AUTOSAR XML (schema 4-0-3)
package /ComponentTypes
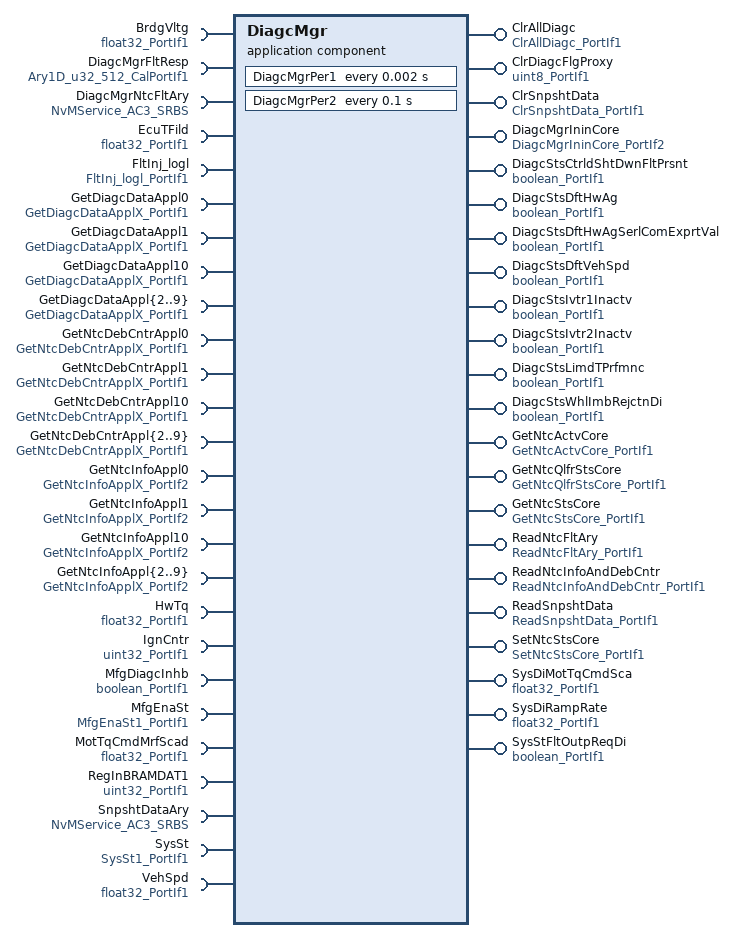
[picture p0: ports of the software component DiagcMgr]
  application sw component type DiagcMgr
    22 x provide port:
      ClrAllDiagc: server-com-spec{operation=Oper, queue-length=1}, provided-interface=ClrAllDiagc_PortIf1
      ClrDiagcFlgProxy: nonqueued-sender-com-spec{data-element=Val, init-value=0}, provided-interface=uint8_PortIf1
      ClrSnpshtData: server-com-spec{operation=Oper, queue-length=1}, provided-interface=ClrSnpshtData_PortIf1
      DiagcMgrIninCore: server-com-spec{operation=Oper, queue-length=1}, provided-interface=DiagcMgrIninCore_PortIf2
      DiagcStsCtrldShtDwnFltPrsnt: nonqueued-sender-com-spec{data-element=Logl, init-value=0}, provided-interface=boolean_PortIf1
      DiagcStsDftHwAg: nonqueued-sender-com-spec{data-element=Logl, init-value=0}, provided-interface=boolean_PortIf1
      DiagcStsDftHwAgSerlComExprtVal: nonqueued-sender-com-spec{data-element=Logl, init-value=0}, provided-interface=boolean_PortIf1
      DiagcStsDftVehSpd: nonqueued-sender-com-spec{data-element=Logl, init-value=0}, provided-interface=boolean_PortIf1
      DiagcStsIvtr1Inactv: nonqueued-sender-com-spec{data-element=Logl, init-value=0}, provided-interface=boolean_PortIf1
      DiagcStsIvtr2Inactv: nonqueued-sender-com-spec{data-element=Logl, init-value=0}, provided-interface=boolean_PortIf1
      DiagcStsLimdTPrfmnc: nonqueued-sender-com-spec{data-element=Logl, init-value=0}, provided-interface=boolean_PortIf1
      DiagcStsWhlImbRejctnDi: nonqueued-sender-com-spec{data-element=Logl, init-value=0}, provided-interface=boolean_PortIf1
      GetNtcActvCore: server-com-spec{operation=Oper, queue-length=1}, provided-interface=GetNtcActvCore_PortIf1
      GetNtcQlfrStsCore: server-com-spec{operation=Oper, queue-length=1}, provided-interface=GetNtcQlfrStsCore_PortIf1
      GetNtcStsCore: server-com-spec{operation=Oper, queue-length=1}, provided-interface=GetNtcStsCore_PortIf1
      ReadNtcFltAry: server-com-spec{operation=Oper, queue-length=1}, provided-interface=ReadNtcFltAry_PortIf1
      ReadNtcInfoAndDebCntr: server-com-spec{operation=Oper, queue-length=1}, provided-interface=ReadNtcInfoAndDebCntr_PortIf1
      ReadSnpshtData: server-com-spec{operation=Oper, queue-length=1}, provided-interface=ReadSnpshtData_PortIf1
      SetNtcStsCore: server-com-spec{operation=Oper, queue-length=1}, provided-interface=SetNtcStsCore_PortIf1
      SysDiMotTqCmdSca: nonqueued-sender-com-spec{data-element=Val, init-value=1}, provided-interface=float32_PortIf1
      SysDiRampRate: nonqueued-sender-com-spec{data-element=Val, init-value=0.1}, provided-interface=float32_PortIf1
      SysStFltOutpReqDi: nonqueued-sender-com-spec{data-element=Logl, init-value=0}, provided-interface=boolean_PortIf1
    47 x require port:
      BrdgVltg: nonqueued-receiver-com-spec{data-element=Val, filter=data-filter-type=ALWAYS, init-value=6}, required-interface=float32_PortIf1
      DiagcMgrFltResp: parameter-require-com-spec{init-value=[0, 2147487488, 2147487488, 2147487488, 2147487488, 2147487488, 2147487488, 2147487488, 2147487488, 2147487488, 2147487488, 2147487488, 2147487488, 2147487488, 2147487488, 2147487488, 2147487488, 2147487488, 2147487488, 2147487488, 2147487488, 2147487488, 2147487488, 2147487488, 2147487488, 2147487488, 2147487488, 2147487488, 2147487488, 2147487488, 2147487488, 2147487488, 2147487488, 2147487488, 2147487488, 2147487488, 2147487488, 2147487488, 2147487488, 2147487488, 2147487488, 2147487488, 2147487488, 2147487488, 2147487488, 2147487488, 2147487488, 2147487488, 2147487488, 2147487488, 2147487488, 2147487488, 2147487488, 2147487488, 2147487488, 2147487488, 2147487488, 2147487488, 2147487488, 2147487488, 2147487488, 2147487488, 2147487488, 2147487488, 2147487488, 2147487488, 2147487488, 2147487488, 2147487488, 2147487488, 2147487488, 2147487488, 2147487488, 2147487488, 2147487488, 2147487488, 2147487488, 2147487488, 2147487488, 2147487488, 2147487488, 2147487488, 2147487488, 2147487488, 2147487488, 2147487488, 2147487488, 2147487488, 2147487488, 2147487488, 2147487488, 2147487488, 2147487488, 2147487488, 2147487488, 2147487488, 2147487488, 2147487488, 2147487488, 2147487488, 2147487488, 2147487488, 2147487488, 2147487488, 2147487488, 2147487488, 2147487488, 2147487488, 2147487488, 2147487488, 2147487488, 2147487488, 2147487488, 2147487488, 2147487488, 2147487488, 2147487488, 2147487488, 2147487488, 2147487488, 2147487488, 2147487488, 2147487488, 2147487488, 2147487488, 2147487488, 2147487488, 2147487488, 2147487488, 2147487488, 2147487488, 2147487488, 2147487488, 2147487488, 2147487488, 2147487488, 2147487488, 2147487488, 2147487488, 2147487488, 2147487488, 2147487488, 2147487488, 2147487488, 2147487488, 2147487488, 2147487488, 2147487488, 2147487488, 2147487488, 2147487488, 2147487488, 2147487488, 2147487488, 2147487488, 2147487488, 2147487488, 2147487488, 2147487488, 2147487488, 2147487488, 2147487488, 2147487488, 2147487488, 2147487488, 2147487488, 2147487488, 2147487488, 2147487488, 2147487488, 2147487488, 2147487488, 2147487488, 2147487488, 2147487488, 2147487488, 2147487488, 2147487488, 2147487488, 2147487488, 2147487488, 2147487488, 2147487488, 2147487488, 2147487488, 2147487488, 2147487488, 2147487488, 2147487488, 2147487488, 2147487488, 2147487488, 2147487488, 2147487488, 2147487488, 2147487488, 2147487488, 2147487488, 2147487488, 2147487488, 2147487488, 2147487488, 2147487488, 2147487488, 2147487488, 2147487488, 2147487488, 2147487488, 2147487488, 2147487488, 2147487488, 2147487488, 2147487488, 2147487488, 2147487488, 2147487488, 2147487488, 2147487488, 2147487488, 2147487488, 2147487488, 2147487488, 2147487488, 2147487488, 2147487488, 2147487488, 2147487488, 2147487488, 2147487488, 2147487488, 2147487488, 2147487488, 2147487488, 2147487488, 2147487488, 2147487488, 2147487488, 2147487488, 2147487488, 2147487488, 2147487488, 2147487488, 2147487488, 2147487488, 2147487488, 2147487488, 2147487488, 2147487488, 2147487488, 2147487488, 2147487488, 2147487488, 2147487488, 2147487488, 2147487488, 2147487488, 2147487488, 2147487488, 2147487488, 2147487488, 2147487488, 2147487488, 2147487488, 2147487488, 2147487488, 2147487488, 2147487488, 2147487488, 2147487488, 2147487488, 2147487488, 2147487488, 2147487488, 2147487488, 2147487488, 2147487488, 2147487488, 2147487488, 2147487488, 2147487488, 2147487488, 2147487488, 2147487488, 2147487488, 2147487488, 2147487488, 2147487488, 2147487488, 2147487488, 2147487488, 2147487488, 2147487488, 2147487488, 2147487488, 2147487488, 2147487488, 2147487488, 2147487488, 2147487488, 2147487488, 2147487488, 2147487488, 2147487488, 2147487488, 2147487488, 2147487488, 2147487488, 2147487488, 2147487488, 2147487488, 2147487488, 2147487488, 2147487488, 2147487488, 2147487488, 2147487488, 2147487488, 2147487488, 2147487488, 2147487488, 2147487488, 2147487488, 2147487488, 2147487488, 2147487488, 2147487488, 2147487488, 2147487488, 2147487488, 2147487488, 2147487488, 2147487488, 2147487488, 2147487488, 2147487488, 2147487488, 2147487488, 2147487488, 2147487488, 2147487488, 2147487488, 2147487488, 2147487488, 2147487488, 2147487488, 2147487488, 2147487488, 2147487488, 2147487488, 2147487488, 2147487488, 2147487488, 2147487488, 2147487488, 2147487488, 2147487488, 2147487488, 2147487488, 2147487488, 2147487488, 2147487488, 2147487488, 2147487488, 2147487488, 2147487488, 2147487488, 2147487488, 2147487488, 2147487488, 2147487488, 2147487488, 2147487488, 2147487488, 2147487488, 2147487488, 2147487488, 2147487488, 2147487488, 2147487488, 2147487488, 2147487488, 2147487488, 2147487488, 2147487488, 2147487488, 2147487488, 2147487488, 2147487488, 2147487488, 2147487488, 2147487488, 2147487488, 2147487488, 2147487488, 2147487488, 2147487488, 2147487488, 2147487488, 2147487488, 2147487488, 2147487488, 2147487488, 2147487488, 2147487488, 2147487488, 2147487488, 2147487488, 2147487488, 2147487488, 2147487488, 2147487488, 2147487488, 2147487488, 2147487488, 2147487488, 2147487488, 2147487488, 2147487488, 2147487488, 2147487488, 2147487488, 2147487488, 2147487488, 2147487488, 2147487488, 2147487488, 2147487488, 2147487488, 2147487488, 2147487488, 2147487488, 2147487488, 2147487488, 2147487488, 2147487488, 2147487488, 2147487488, 2147487488, 2147487488, 2147487488, 2147487488, 2147487488, 2147487488, 2147487488, 2147487488, 2147487488, 2147487488, 2147487488, 2147487488, 2147487488, 2147487488, 2147487488, 2147487488, 2147487488, 2147487488, 2147487488, 2147487488, 2147487488, 2147487488, 2147487488, 2147487488, 2147487488, 2147487488, 2147487488, 2147487488, 2147487488, 2147487488, 2147487488, 2147487488, 2147487488, 2147487488, 2147487488, 2147487488, 2147487488, 2147487488, 2147487488, 2147487488, 2147487488, 2147487488, 2147487488, 2147487488, 2147487488, 2147487488, 2147487488, 2147487488, 2147487488, 2147487488, 2147487488, 2147487488, 2147487488, 2147487488, 2147487488, 2147487488, 2147487488, 2147487488, 2147487488, 2147487488, 2147487488, 2147487488, 2147487488, 2147487488, 2147487488, 2147487488, 2147487488, 2147487488, 2147487488, 2147487488, 2147487488, 2147487488, 2147487488, 2147487488, 2147487488], parameter=Ary1D}, required-interface=Ary1D_u32_512_CalPortIf1
      DiagcMgrNtcFltAry: required-interface=NvMService_AC3_SRBS
      EcuTFild: nonqueued-receiver-com-spec{data-element=Val, filter=data-filter-type=ALWAYS, init-value=25}, required-interface=float32_PortIf1
      FltInj_logl: required-interface=FltInj_logl_PortIf1
      GetDiagcDataAppl0: required-interface=GetDiagcDataApplX_PortIf1
      GetDiagcDataAppl1: required-interface=GetDiagcDataApplX_PortIf1
      GetDiagcDataAppl10: required-interface=GetDiagcDataApplX_PortIf1
      GetDiagcDataAppl{2..9}: required-interface=GetDiagcDataApplX_PortIf1
      GetNtcDebCntrAppl0: required-interface=GetNtcDebCntrApplX_PortIf1
      GetNtcDebCntrAppl1: required-interface=GetNtcDebCntrApplX_PortIf1
      GetNtcDebCntrAppl10: required-interface=GetNtcDebCntrApplX_PortIf1
      GetNtcDebCntrAppl{2..9}: required-interface=GetNtcDebCntrApplX_PortIf1
      GetNtcInfoAppl0: required-interface=GetNtcInfoApplX_PortIf2
      GetNtcInfoAppl1: required-interface=GetNtcInfoApplX_PortIf2
      GetNtcInfoAppl10: required-interface=GetNtcInfoApplX_PortIf2
      GetNtcInfoAppl{2..9}: required-interface=GetNtcInfoApplX_PortIf2
      HwTq: nonqueued-receiver-com-spec{data-element=Val, filter=data-filter-type=ALWAYS, init-value=0}, required-interface=float32_PortIf1
      IgnCntr: nonqueued-receiver-com-spec{data-element=Val, filter=data-filter-type=ALWAYS, init-value=0}, required-interface=uint32_PortIf1
      MfgDiagcInhb: nonqueued-receiver-com-spec{data-element=Logl, filter=data-filter-type=ALWAYS, init-value=0}, required-interface=boolean_PortIf1
      MfgEnaSt: nonqueued-receiver-com-spec{data-element=Val, filter=data-filter-type=ALWAYS, init-value=0}, required-interface=MfgEnaSt1_PortIf1
      MotTqCmdMrfScad: nonqueued-receiver-com-spec{data-element=Val, filter=data-filter-type=ALWAYS, init-value=0}, required-interface=float32_PortIf1
      RegInBRAMDAT1: nonqueued-receiver-com-spec{data-element=Val, filter=data-filter-type=ALWAYS, init-value=0}, required-interface=uint32_PortIf1
      SnpshtDataAry: required-interface=NvMService_AC3_SRBS
      SysSt: nonqueued-receiver-com-spec{data-element=Val, filter=data-filter-type=ALWAYS, init-value=3}, required-interface=SysSt1_PortIf1
      VehSpd: nonqueued-receiver-com-spec{data-element=Val, filter=data-filter-type=ALWAYS, init-value=0}, required-interface=float32_PortIf1
    behavior DiagcMgr_InternalBehavior: data-type-mapping=Nexteer
      exclusive area DiagcMgrExclusiveArea
      ar-typed-per-instance-memorys:
        6 x data:
          ClrDiagcFlg: sw-calibration-access=READ-ONLY, type=uint8
          DiagcMgrNtcFltAry: sw-calibration-access=READ-ONLY, type=Ary1D_NtcFltInfoRec2_20
          DtcEnaSts: sw-calibration-access=READ-ONLY, type=uint16
          DtcIdxPrevSts: type=Ary1D_u08_DiagcMgr1
          PrevClrDtcFlg: sw-calibration-access=READ-ONLY, type=uint8
          SnpshtDataAry: sw-calibration-access=READ-ONLY, type=Ary1D_SnpshtDataRec1_8
      operation invoked event OIT_ClrAllDiagc_Oper_ClrAllDiagc_Oper: start-on-event=ClrAllDiagc_Oper, operation=ClrAllDiagc.Oper
      operation invoked event OIT_ClrSnpshtData_Oper_ClrSnpshtData_Oper: start-on-event=ClrSnpshtData_Oper, operation=ClrSnpshtData.Oper
      operation invoked event OIT_DiagcMgrIninCore_Oper_DiagcMgrIninCore_Oper: start-on-event=DiagcMgrIninCore_Oper, operation=DiagcMgrIninCore.Oper
      timing event TMT_DiagcMgrPer1: start-on-event=DiagcMgrPer1, period=0.002
      timing event TMT_DiagcMgrPer2: start-on-event=DiagcMgrPer2, period=0.1
      7 x operation invoked event:
        OIT_GetNtcActvCore_Oper_GetNtcActvCore_Oper: start-on-event=GetNtcActvCore_Oper, operation=GetNtcActvCore.Oper
        OIT_GetNtcQlfrStsCore_Oper_GetNtcQlfrStsCore_Oper: start-on-event=GetNtcQlfrStsCore_Oper, operation=GetNtcQlfrStsCore.Oper
        OIT_GetNtcStsCore_Oper_GetNtcStsCore_Oper: start-on-event=GetNtcStsCore_Oper, operation=GetNtcStsCore.Oper
        OIT_ReadNtcFltAry_Oper_ReadNtcFltAry_Oper: start-on-event=ReadNtcFltAry_Oper, operation=ReadNtcFltAry.Oper
        OIT_ReadNtcInfoAndDebCntr_Oper_ReadNtcInfoAndDebCntr_Oper: start-on-event=ReadNtcInfoAndDebCntr_Oper, operation=ReadNtcInfoAndDebCntr.Oper
        OIT_ReadSnpshtData_Oper_ReadSnpshtData_Oper: start-on-event=ReadSnpshtData_Oper, operation=ReadSnpshtData.Oper
        OIT_SetNtcStsCore_Oper_SetNtcStsCore_Oper: start-on-event=SetNtcStsCore_Oper, operation=SetNtcStsCore.Oper
      12 x runnable:
        ClrAllDiagc_Oper: can-be-invoked-concurrently=true
          data-send-points:
            access SEND_ClrDiagcFlg_Val: accessed-variable=ClrDiagcFlgProxy.Val
        ClrSnpshtData_Oper
        DiagcMgrIninCore_Oper: can-be-invoked-concurrently=true
        DiagcMgrPer1: can-enter-exclusive-area=DiagcMgrExclusiveArea
          data-send-points:
            11 x access:
              SEND_DiagcStsCtrldShtDwnFltPrsnt_Logl: accessed-variable=DiagcStsCtrldShtDwnFltPrsnt.Logl
              SEND_DiagcStsDftHwAg_Logl: accessed-variable=DiagcStsDftHwAg.Logl
              SEND_DiagcStsDftHwAgSerlComExprtVal_Logl: accessed-variable=DiagcStsDftHwAgSerlComExprtVal.Logl
              SEND_DiagcStsDftVehSpd_Logl: accessed-variable=DiagcStsDftVehSpd.Logl
              SEND_DiagcStsIvtr1Inactv_Logl: accessed-variable=DiagcStsIvtr1Inactv.Logl
              SEND_DiagcStsIvtr2Inactv_Logl: accessed-variable=DiagcStsIvtr2Inactv.Logl
              SEND_DiagcStsLimdTPrfmnc_Logl: accessed-variable=DiagcStsLimdTPrfmnc.Logl
              SEND_DiagcStsWhlImbRejctnDi_Logl: accessed-variable=DiagcStsWhlImbRejctnDi.Logl
              SEND_SysDiMotTqCmdSca_Val: accessed-variable=SysDiMotTqCmdSca.Val
              SEND_SysDiRampRate_Val: accessed-variable=SysDiRampRate.Val
              SEND_SysStFltOutpReqDi_Logl: accessed-variable=SysStFltOutpReqDi.Logl
          12 x sync call, all with timeout=0:
            SC_FltInj_Oper: operation=FltInj_logl.Oper
            SC_GetDiagcDataAppl0_Oper: operation=GetDiagcDataAppl0.Oper
            SC_GetDiagcDataAppl1_Oper: operation=GetDiagcDataAppl1.Oper
            SC_GetDiagcDataAppl10_Oper: operation=GetDiagcDataAppl10.Oper
            SC_GetDiagcDataAppl{2..9}_Oper: operation=GetDiagcDataAppl{2..9}.Oper
        DiagcMgrPer2
        GetNtcActvCore_Oper: can-be-invoked-concurrently=true
        GetNtcQlfrStsCore_Oper: can-be-invoked-concurrently=true
        GetNtcStsCore_Oper: can-be-invoked-concurrently=true
        ReadNtcFltAry_Oper
          11 x sync call, all with timeout=0:
            SC_GetNtcInfoAppl0_Oper: operation=GetNtcInfoAppl0.Oper
            SC_GetNtcInfoAppl1_Oper: operation=GetNtcInfoAppl1.Oper
            SC_GetNtcInfoAppl10_Oper: operation=GetNtcInfoAppl10.Oper
            SC_GetNtcInfoAppl{2..9}_Oper: operation=GetNtcInfoAppl{2..9}.Oper
        ReadNtcInfoAndDebCntr_Oper
          22 x sync call, all with timeout=0:
            SC_GetNtcDebCntrAppl0_Oper: operation=GetNtcDebCntrAppl0.Oper
            SC_GetNtcDebCntrAppl1_Oper: operation=GetNtcDebCntrAppl1.Oper
            SC_GetNtcDebCntrAppl10_Oper: operation=GetNtcDebCntrAppl10.Oper
            SC_GetNtcDebCntrAppl{2..9}_Oper: operation=GetNtcDebCntrAppl{2..9}.Oper
            SC_GetNtcInfoAppl0_Oper: operation=GetNtcInfoAppl0.Oper
            SC_GetNtcInfoAppl1_Oper: operation=GetNtcInfoAppl1.Oper
            SC_GetNtcInfoAppl10_Oper: operation=GetNtcInfoAppl10.Oper
            SC_GetNtcInfoAppl{2..9}_Oper: operation=GetNtcInfoAppl{2..9}.Oper
        ReadSnpshtData_Oper
        SetNtcStsCore_Oper: can-enter-exclusive-area=DiagcMgrExclusiveArea, can-be-invoked-concurrently=true
          data-receive-point-by-arguments:
            10 x access:
              REC_BrdgVltg_Val: accessed-variable=BrdgVltg.Val
              REC_EcuTFild_Val: accessed-variable=EcuTFild.Val
              REC_Hwtq_Val: accessed-variable=HwTq.Val
              REC_IgnCntr_Val_1: accessed-variable=IgnCntr.Val
              REC_MfgDiagcInhb_Logl: accessed-variable=MfgDiagcInhb.Logl
              REC_MfgEnaSt_Val: accessed-variable=MfgEnaSt.Val
              REC_MotTqCmdMrfScad_Val: accessed-variable=MotTqCmdMrfScad.Val
              REC_RegInBRAMDAT1_Val: accessed-variable=RegInBRAMDAT1.Val
              REC_SysSt_Val: accessed-variable=SysSt.Val
              REC_VehSpd_Val: accessed-variable=VehSpd.Val
          sync call SC_SnpshtDataAry_SetRamBlockStatus: operation=SnpshtDataAry.SetRamBlockStatus, timeout=0
      swc service dependency NvmDiagcMgrNtcFltAry: assigned-datas=role-based-data-assignment={role=ramBlock, used-data-element=DiagcMgrNtcFltAry}
        assigned-ports:
          port-prototype=DiagcMgrNtcFltAry, role=NvMService_AC3_SRBS
          port-prototype=DiagcMgrNtcFltAry, role=NvMService_AC3_SRBS
        service-needs:
          nv block needs NvmDiagcMgrNtcFltAry: n-data-sets=0, readonly=false, reliability=ERROR-DETECTION, resistant-to-changed-sw=true, restore-at-start=true, store-at-shutdown=true, write-only-once=false, writing-frequency=0, writing-priority=LOW
      swc service dependency NvmSnpshtDataAry: assigned-datas=role-based-data-assignment={role=ramBlock, used-data-element=SnpshtDataAry}
        assigned-ports:
          port-prototype=SnpshtDataAry, role=NvMService_AC3_SRBS
          port-prototype=SnpshtDataAry, role=NvMService_AC3_SRBS
        service-needs:
          nv block needs NvmSnpshtDataAry: n-data-sets=0, readonly=false, reliability=ERROR-DETECTION, resistant-to-changed-sw=false, restore-at-start=false, store-at-shutdown=false, write-only-once=false, writing-frequency=0, writing-priority=LOW
  swc implementation DiagcMgr_Implementation: behavior=DiagcMgr_InternalBehavior
    code-descriptors:
      code Default: artifact-descriptors=autosar-engineering-object={short-label=Default, category=SWSRC}
